# 3065PNPIRA register map
File version: 1.0
Registers are 32-bit, access per field, reset 0x0 unless marked. A register's access mark holds for its fields unless they carry their own. Offsets are from the block's base; [hi:lo] are bit positions; {n}, {i} and the like mark numbered series; 'fields as' and 'values as' point back to an identical list.

## IOCMG_CORE — IOCMG_CORE peripheral interface
Base 0x147F0000
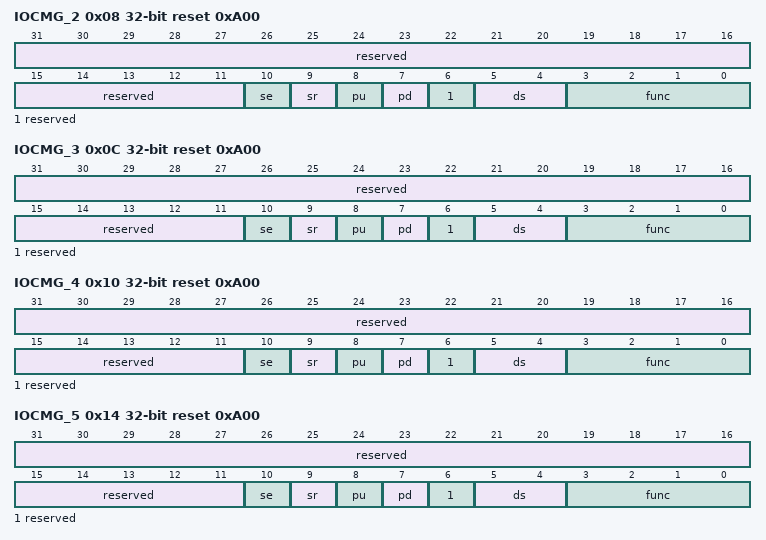
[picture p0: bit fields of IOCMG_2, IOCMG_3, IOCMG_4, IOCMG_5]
0x08 IOCMG_2 reset 0xA00 — IOCMG_2为GPIO0_2管脚配置寄存器。
  [31:11] reserved ro — 保留。
  [10] se rw — 管脚施密特输入控制。 0：关闭； 1：打开。
  [9] sr rw — 管脚电平转换速率控制。 0：快沿输出； 1：慢沿输出。
  [8] pu rw — 管脚上拉控制。 0：关闭； 1：打开。
  [7] pd rw — 管脚下拉控制。 0：关闭； 1：打开。
  [6] reserved ro — 保留。
  [5:4] ds rw — 管脚驱动能力选择（档位越大，驱动能力越大）。 00：档位1； 01：档位2； 10：档位3； 11：档位4。
  [3:0] func rw — 功能选择。 管脚复用功能选择。 具体复用功能请参考《3066M / 3065P系列数据手册》。
0x0C IOCMG_3 reset 0xA00 — IOCMG_3为XTAL_OUT管脚配置寄存器。
  fields as IOCMG_2
0x10 IOCMG_4 reset 0xA00 — IOCMG_4为XTAL_IN管脚配置寄存器。
  fields as IOCMG_2
0x14 IOCMG_5 reset 0xA00 — IOCMG_5为GPT0管脚配置寄存器。
  fields as IOCMG_2
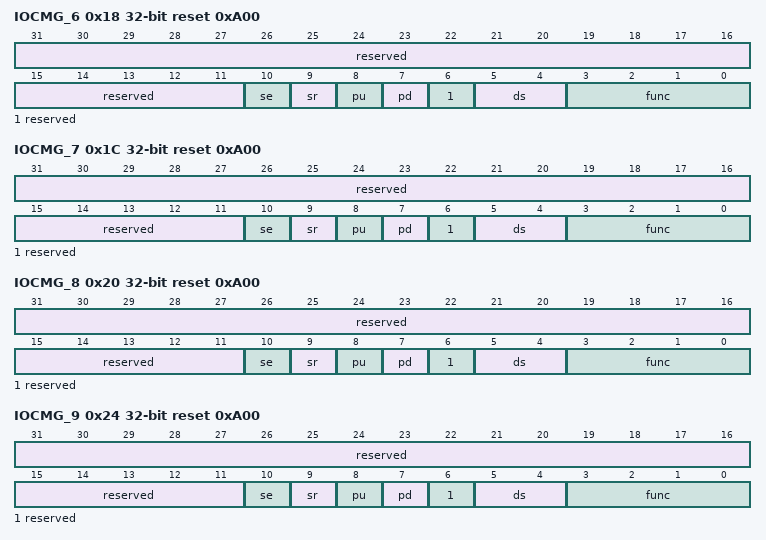
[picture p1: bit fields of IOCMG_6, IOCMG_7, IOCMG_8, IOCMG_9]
0x18 IOCMG_6 reset 0xA00 — IOCMG_6为CAN0_RX管脚配置寄存器。
  fields as IOCMG_2
0x1C IOCMG_7 reset 0xA00 — IOCMG_7为CAN0_TX管脚配置寄存器。
  fields as IOCMG_2
0x20 IOCMG_8 reset 0xA00 — IOCMG_8为QDM0_A管脚配置寄存器。
  fields as IOCMG_2
0x24 IOCMG_9 reset 0xA00 — IOCMG_9为QDM0_B管脚配置寄存器。
  fields as IOCMG_2
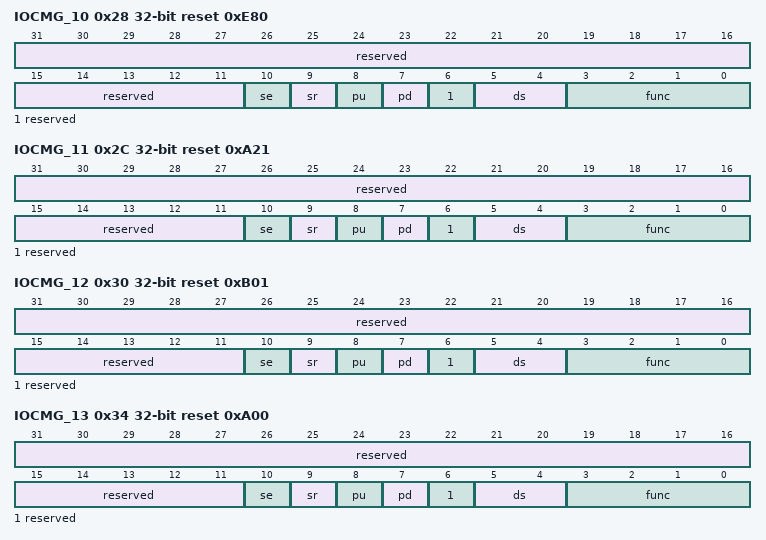
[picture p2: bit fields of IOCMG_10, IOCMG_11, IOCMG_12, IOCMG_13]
0x28 IOCMG_10 reset 0xE80 — IOCMG_10为BOOT/GPIO1_2管脚配置寄存器。
  fields as IOCMG_2
0x2C IOCMG_11 reset 0xA21 — IOCMG_11为TDO/GPT1/UART1_RX管脚配置寄存器。
  fields as IOCMG_2
0x30 IOCMG_12 reset 0xB01 — IOCMG_12为TDI/CAPMO/UART1_TX管管脚配置寄存器。
  fields as IOCMG_2
0x34 IOCMG_13 reset 0xA00 — IOCMG_13为GPIO1_5管脚配置寄存器。
  fields as IOCMG_2
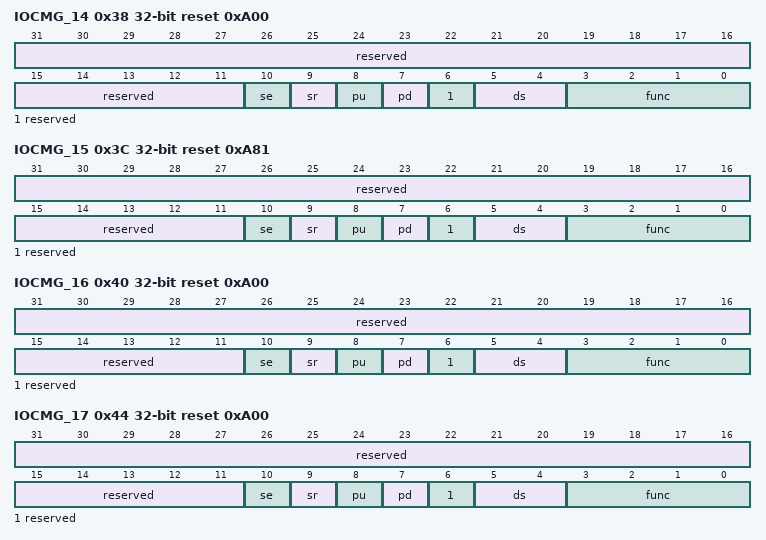
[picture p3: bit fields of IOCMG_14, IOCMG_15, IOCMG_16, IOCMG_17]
0x38 IOCMG_14 reset 0xA00 — IOCMG_14为QDM0_INDEX/POE1管脚配置寄存器。
  fields as IOCMG_2
0x3C IOCMG_15 reset 0xA81 — IOCMG_15为TRST_N/ADC1_A11/CAPM1管脚配置寄存器。
  fields as IOCMG_2
0x40 IOCMG_16 reset 0xA00 — IOCMG_16为ADC1_A12/CAPM2管脚配置寄存器。
  fields as IOCMG_2
0x44 IOCMG_17 reset 0xA00 — IOCMG_17为ADC1_A13管脚配置寄存器。
  fields as IOCMG_2
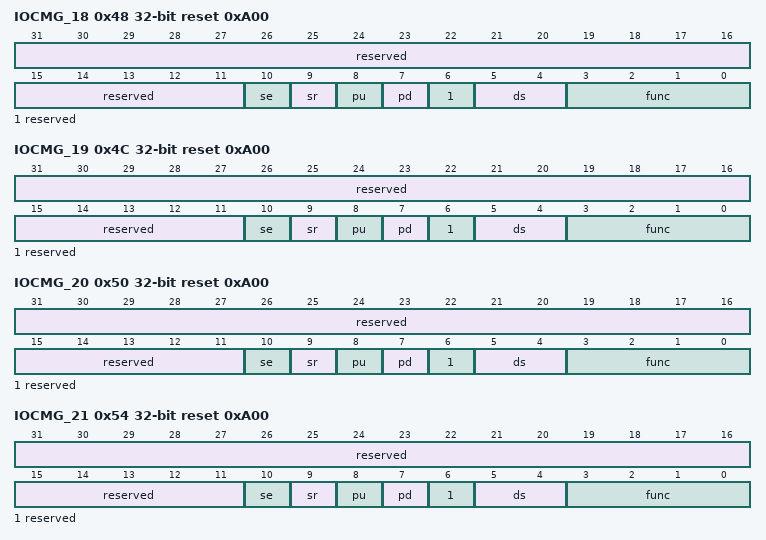
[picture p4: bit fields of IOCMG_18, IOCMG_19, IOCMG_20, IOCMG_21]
0x48 IOCMG_18 reset 0xA00 — IOCMG_18为ADC1_A8管脚配置寄存器。
  fields as IOCMG_2
0x4C IOCMG_19 reset 0xA00 — IOCMG_19为ADC1_A2/PGA1IN_P0管脚配置寄存器。
  fields as IOCMG_2
0x50 IOCMG_20 reset 0xA00 — IOCMG_20为ADC1_A10/PGA1IN_N0/APT6_A管脚配置寄存器。
  fields as IOCMG_2
0x54 IOCMG_21 reset 0xA00 — IOCMG_21为PGA1OUT0管脚配置寄存器。
  fields as IOCMG_2
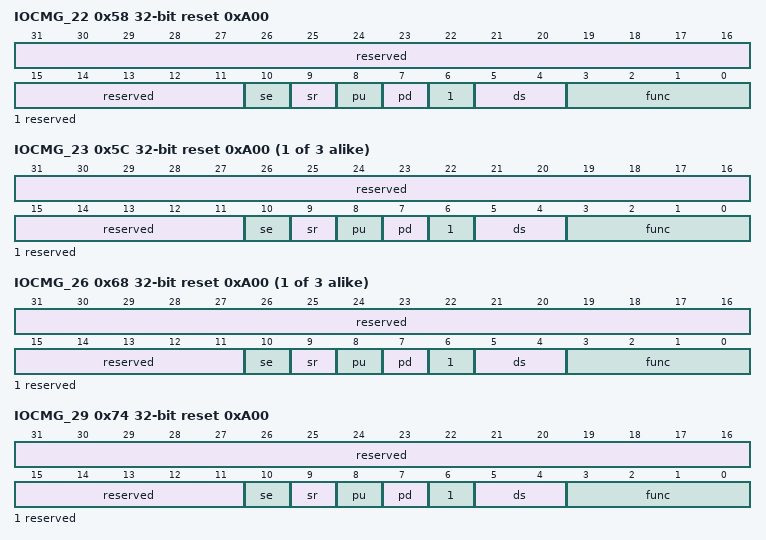
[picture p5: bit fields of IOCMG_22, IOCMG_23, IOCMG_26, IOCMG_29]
0x58 IOCMG_22 reset 0xA00 — IOCMG_22为ADC1_A3管脚配置寄存器。
  fields as IOCMG_2
{0x0+4i} IOCMG_{i} reset 0xA00 (i=23..25) — IOCMG_{i}为ADC1_A{i-19}/APT{i-17}_B管脚配置寄存器。
  fields as IOCMG_2
{0x0+4i} IOCMG_{i} reset 0xA00 (i=26..28) — IOCMG_{i}为GPIO3_{i-24}管脚配置寄存器。
  fields as IOCMG_2
0x74 IOCMG_29 reset 0xA00 — IOCMG_29为APTO_A管脚配置寄存器。
  fields as IOCMG_2
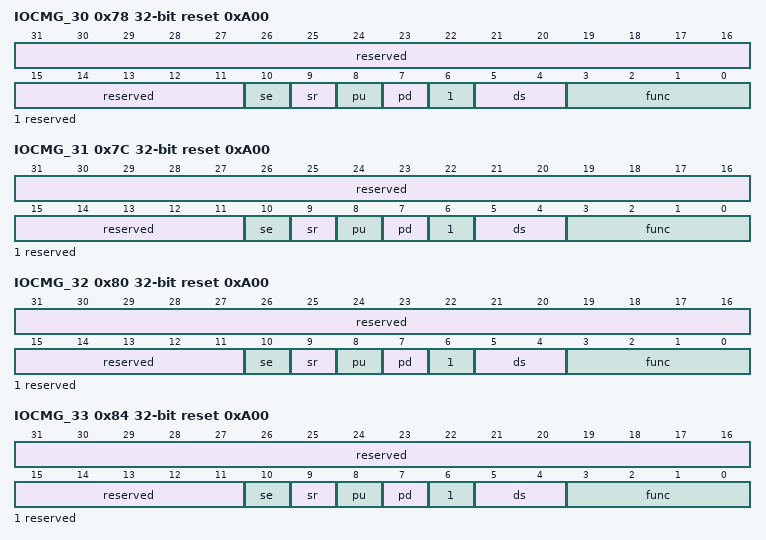
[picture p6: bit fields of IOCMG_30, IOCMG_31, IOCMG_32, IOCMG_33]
0x78 IOCMG_30 reset 0xA00 — IOCMG_30为APT1_A管脚配置寄存器。
  fields as IOCMG_2
0x7C IOCMG_31 reset 0xA00 — IOCMG_31为APT2_A管脚配置寄存器。
  fields as IOCMG_2
0x80 IOCMG_32 reset 0xA00 — IOCMG_32为APTO_B管脚配置寄存器。
  fields as IOCMG_2
0x84 IOCMG_33 reset 0xA00 — IOCMG_33为APT1_B管脚配置寄存器。
  fields as IOCMG_2
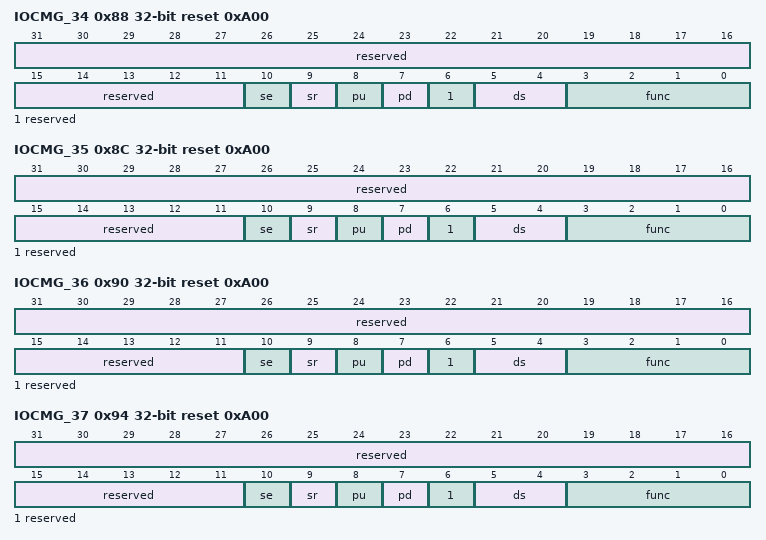
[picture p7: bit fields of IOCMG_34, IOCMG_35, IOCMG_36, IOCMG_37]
0x88 IOCMG_34 reset 0xA00 — IOCMG_34为APT2_B管脚配置寄存器。
  fields as IOCMG_2
0x8C IOCMG_35 reset 0xA00 — IOCMG_35为PGA0IN_P0管脚配置寄存器。
  fields as IOCMG_2
0x90 IOCMG_36 reset 0xA00 — IOCMG_36为PGA0IN_N0管脚配置寄存器。
  fields as IOCMG_2
0x94 IOCMG_37 reset 0xA00 — IOCMG_37为PGA0OUT管脚配置寄存器。
  fields as IOCMG_2
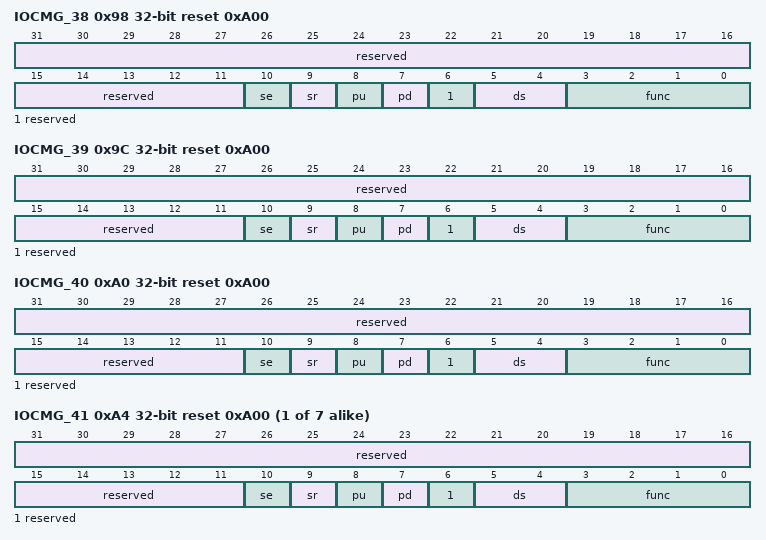
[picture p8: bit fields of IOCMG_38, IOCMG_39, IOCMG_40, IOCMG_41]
0x98 IOCMG_38 reset 0xA00 — IOCMG_38为GPIO4_6管脚配置寄存器。
  fields as IOCMG_2
0x9C IOCMG_39 reset 0xA00 — IOCMG_39为GPIO4_7管脚配置寄存器。
  fields as IOCMG_2
0xA0 IOCMG_40 reset 0xA00 — IOCMG_40为GPIO5_0/POE0管脚配置寄存器。
  fields as IOCMG_2
{0x0+4i} IOCMG_{i} reset 0xA00 (i=41..47) — IOCMG_{i}为GPIO5_{i-40}管脚配置寄存器。
  fields as IOCMG_2
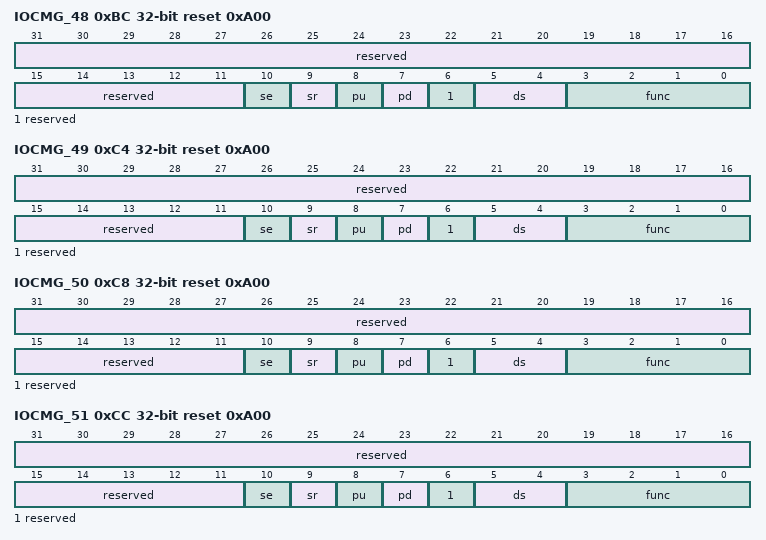
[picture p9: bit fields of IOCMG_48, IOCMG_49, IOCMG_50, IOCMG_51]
0xBC IOCMG_48 reset 0xA00 — IOCMG_48为ADC2_A7管脚配置寄存器。
  fields as IOCMG_2
0xC4 IOCMG_49 reset 0xA00 — IOCMG_49为ADC2_A8管脚配置寄存器。
  fields as IOCMG_2
0xC8 IOCMG_50 reset 0xA00 — IOCMG_50为ADC2_A5管脚配置寄存器。
  fields as IOCMG_2
0xCC IOCMG_51 reset 0xA00 — IOCMG_51为ADC2_A2/POE2管脚配置寄存器。
  fields as IOCMG_2
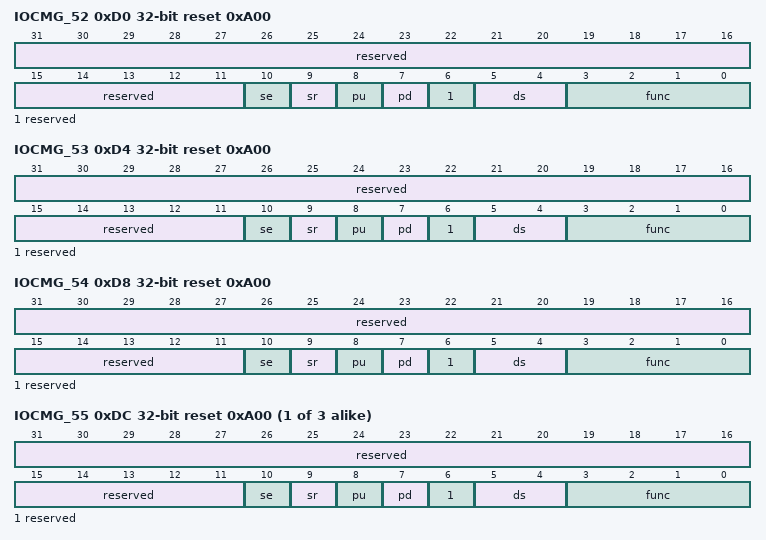
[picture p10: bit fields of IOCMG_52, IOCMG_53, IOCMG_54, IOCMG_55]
0xD0 IOCMG_52 reset 0xA00 — IOCMG_52为ADC2_A10管管脚配置寄存器。
  fields as IOCMG_2
0xD4 IOCMG_53 reset 0xA00 — IOCMG_53为GPIO6_5管脚配置寄存器。
  fields as IOCMG_2
0xD8 IOCMG_54 reset 0xA00 — IOCMG_54为GPIO6_6管脚配置寄存器。
  fields as IOCMG_2
{0x0+4i} IOCMG_{i} reset 0xA00 (i=55..57) — IOCMG_{i}为APT{i-52}_A管脚配置寄存器。
  fields as IOCMG_2
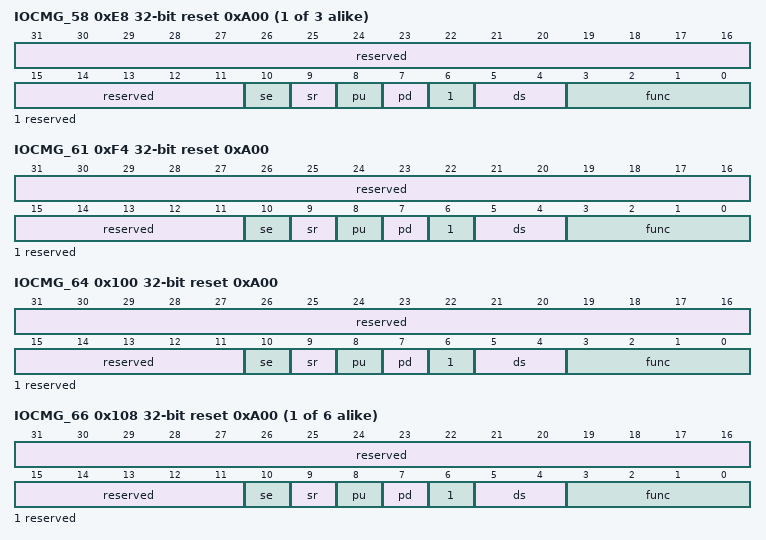
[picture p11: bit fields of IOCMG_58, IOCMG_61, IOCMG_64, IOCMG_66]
{0x0+4i} IOCMG_{i} reset 0xA00 (i=58..60) — IOCMG_{i}为APT{i-55}_B管脚配置寄存器。
  fields as IOCMG_2
0xF4 IOCMG_61 reset 0xA00 — IOCMG_61为GPIO7_5管脚配置寄存器。
  fields as IOCMG_2
0x100 IOCMG_64 reset 0xA00 — IOCMG_64为GPIO8_0管脚配置寄存器。
  fields as IOCMG_2
{0x0+4i} IOCMG_{i} reset 0xA00 (i=66..71) — IOCMG_{i}为GPIO8_{i-64}管脚配置寄存器。
  fields as IOCMG_2
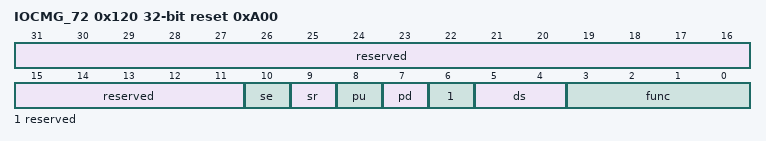
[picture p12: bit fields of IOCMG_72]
0x120 IOCMG_72 reset 0xA00 — IOCMG_72为GPIO9_0管脚配置寄存器。
  fields as IOCMG_2
